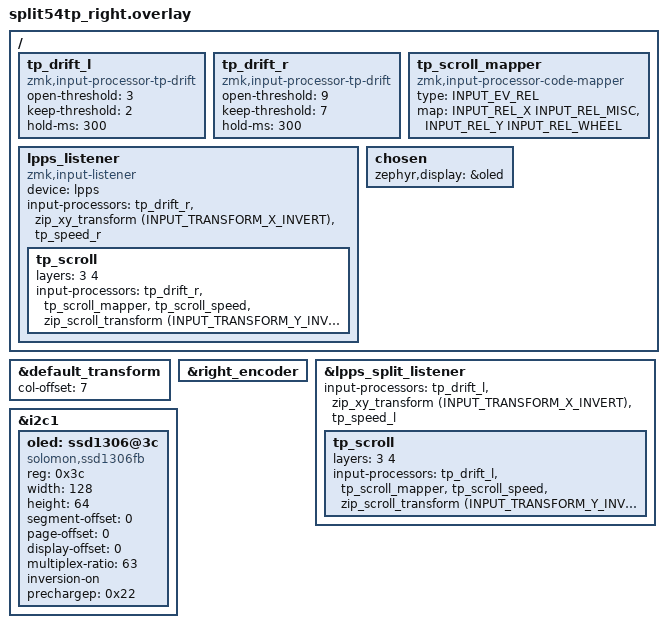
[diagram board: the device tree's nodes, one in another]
/*
 * split54tp 右半身 (セントラル)
 * USB/BLEでホストに接続する側。
 */

#include "split54tp.dtsi"
#include <input/processors.dtsi>
#include <dt-bindings/zmk/input_transform.h>

/* 右半身は transform の列 7-13 を使用 */
&default_transform {
    col-offset = <7>;
};

&right_encoder {
    status = "okay";

    /*
     * ⚠ 右基板は ENC1 を物理的に180度回転して実装している。
     *   実機で回転方向が左と逆だった場合は、下の2行のコメントを外して
     *   a/b を入れ替える (ファームウェアだけで直せる)。
     *
     * ★ 2026-09-05 実機で確認: 一般的なマウスホイールと回転方向が逆だった。
     *   予見どおりだったので、下の2行を有効化して a/b を入れ替える。
     *   左基板は回転させていないので入れ替えない。これで左右が揃う。
     *   元に戻すには下の2行を削除する (dtsi の a=D7 / b=D8 に戻る)。
     *
     * ★ 2026-09-26 rev.6 実機: この入れ替えがあると左右で回転方向が逆になった
     *   (左 = 一般的なマウスと同じ / 右 = 逆)。rev.6 の右基板は ENC1 を回転実装して
     *   いないため、入れ替えを外す (dtsi の a=D7 / b=D8 のまま)。
     *   rev.5 用の入れ替えは split54tp_right.overlay.bak-enc-20260926 に残してある。
     */
    // a-gpios = <&xiao_d 8 (GPIO_ACTIVE_HIGH | GPIO_PULL_UP)>;
    // b-gpios = <&xiao_d 7 (GPIO_ACTIVE_HIGH | GPIO_PULL_UP)>;
};

/*
 * ---- ポインティングスティック ---- 2026-09-26 有効化
 * 右はセントラル。
 *   ・自分の LPPS (dtsi の &lpps) → lpps_listener
 *   ・左の LPPS (input-split 経由) → lpps_split_listener
 *
 * ★ 軸の向き: 実機で「上に倒したのに下へ動く」等があれば、
 *   該当する listener に input-processors を足す (左は &lpps_split_listener に足す)。
 *     #include <dt-bindings/zmk/input_transform.h>
 *     input-processors = <&zip_xy_transform (INPUT_TRANSFORM_X_INVERT)>;
 *   使える値: INPUT_TRANSFORM_XY_SWAP / _X_INVERT / _Y_INVERT
 *   https://zmk.dev/docs/keymaps/input-processors/transformer
 */
/*
 * ★ 2026-11-11 (ユーザー指定) L1 / L2 を押している間、スティック (左右とも) を上下スクロールにする。
 *   ZMK の input listener の「レイヤーごとの差し替え」(子ノードの layers / input-processors) を使う。
 *   https://zmk.dev/docs/keymaps/input-processors/usage
 *   layers の 3 / 4 はキーマップの LOWER (L1) / RAISE (L2)。キーマップの #define と合わせること。
 *   中身: 上下 (Y) をホイールへ、左右 (X) は捨てる (tp_scroll_mapper) → 速さ (&tp_scroll_speed、split54tp.dtsi。設定レイヤーで上げ下げ)
 *         → ホイールの向きを逆にする (&zip_scroll_transform Y_INVERT。上に倒すと上へスクロール = Windows のふつうの向き。ユーザー: 向きは良い)。
 *   ★ 2026-11-11 最初は 1/8 固定 (&zip_y_scaler 1 8) で「爆速すぎ」(ユーザー) → 段で変えられる &tp_scroll_speed (既定 1/50) にした。
 *   L1 / L2 の間はカーソルが動かない (左右も捨てるので斜めに倒しても横スクロールしない)。感度 (tp_speed) は効かない。
 *   逆向きにしたいときは zip_scroll_transform を消す。
 */
/*
 * ★ 2026-11-11 (3 回目) ドリフト止め (ユーザー: 「左右どちらかは不明だがドリフトがひどい。何度 TP 校正をしてもすぐ動き始める」)。
 *   自作の input processor (src/pointing/input_processor_tp_drift.c) の「門」を、左右それぞれのいちばん前に置く
 *   (L1 / L2 のスクロールの差し替え tp_scroll にも。差し替えると元の並びは使われないため)。
 *   門が閉じている間は小さな動き (ドリフト) を捨てる。生の値 (絶対値) が open-threshold 以上で開き、
 *   hold-ms の間は通す。開いている間は keep-threshold 以上の値で延びる。
 *   値は推測で決めた (ドリフトの大きさはまだ測っていない)。F / J (TP 復旧) の 2 行目の V に、自分の側のドリフトの最大の値が出るので、
 *   それより 1 大きい open-threshold にする。止めたいときは open-threshold = <0>。
 *   (TP 復旧は 2026-11-11 に G / H へ移動)
 * ★ 2026-11-11 (4 回目) 右を open 9 / keep 7 に (左は 3 / 2 のまま)。実測 (ユーザー、H で 30 秒触らずに): 右は
 *   シュラウドとキャップを付けたまま V54、外して V5、もう一度 V6 (V34 は、前に押してからの部品を外した間を含むとみる。未確認)。
 *   最大 6 に余裕を見て、開くのは 9 以上、開いている間は 7 以上で延びる (ドリフトの 6 以下では開いたままにならない)。
 *   代わりに右は、ゆっくり倒し始めたときに 9 の力まで動かない。左のドリフトは未測定。
 */
/ {
    tp_drift_l: tp_drift_l {
        compatible = "zmk,input-processor-tp-drift";
        #input-processor-cells = <0>;
        open-threshold = <3>;
        keep-threshold = <2>;
        hold-ms = <300>;
    };

    tp_drift_r: tp_drift_r {
        compatible = "zmk,input-processor-tp-drift";
        #input-processor-cells = <0>;
        open-threshold = <9>;   /* ★ 2026-11-11 (4 回目) 3 → 9 */
        keep-threshold = <7>;   /* ★ 2026-11-11 (4 回目) 2 → 7 */
        hold-ms = <300>;
    };
};

/ {
    /* 上下 (Y) だけをホイールへ。左右 (X) は INPUT_REL_MISC にして捨てる (ZMK の input_listener.c は REL の X / Y / WHEEL / HWHEEL 以外を無視する) */
    tp_scroll_mapper: tp_scroll_mapper {
        compatible = "zmk,input-processor-code-mapper";
        #input-processor-cells = <0>;
        type = <INPUT_EV_REL>;
        map = <INPUT_REL_X INPUT_REL_MISC>, <INPUT_REL_Y INPUT_REL_WHEEL>;
    };

    lpps_listener: lpps_listener {
        compatible = "zmk,input-listener";
        device = <&lpps>;
        /* ★ 2026-11-04 &tp_speed_r = 右の感度 (split54tp.dtsi / 設定レイヤーで上げ下げ) */
        /* ★ 2026-11-11 (3 回目) いちばん前に &tp_drift_r (ドリフト止め) */
        input-processors = <&tp_drift_r &zip_xy_transform (INPUT_TRANSFORM_X_INVERT) &tp_speed_r>;

        /* ★ 2026-11-11 L1 (3) / L2 (4) の間は上下スクロール */
        tp_scroll {
            layers = <3 4>;
            input-processors = <&tp_drift_r &tp_scroll_mapper &tp_scroll_speed &zip_scroll_transform (INPUT_TRANSFORM_Y_INVERT)>;
        };
    };
};

/*
 * ⚠ 2026-09-26 一時停止: 左スティックがドリフトし続ける (倒しても反応しない)。
 *   ログで右は x=0 y=0 (z のみ) と確認、ドリフト源は左 (input-split 経由) と特定。
 *   左センサの半田を直したら status を "okay" に戻す。
 * ★ 2026-10-25 rev.7: センサを新品 (SK8707-01-004) に替えるので、左の受信を戻す。
 *   また左がドリフトするなら、下を "disabled" に戻して切り分ける。
 */
&lpps_split_listener {
    status = "okay";
    /* ★ 2026-11-04 &tp_speed_l = 左の感度。左のスティックの分もここ (右) で計算するので、感度だけなら左の書き直しは要らない */
    /* ★ 2026-11-11 (3 回目) いちばん前に &tp_drift_l (ドリフト止め) */
    input-processors = <&tp_drift_l &zip_xy_transform (INPUT_TRANSFORM_X_INVERT) &tp_speed_l>;

    /* ★ 2026-11-11 L1 (3) / L2 (4) の間は上下スクロール (右の lpps_listener と同じ) */
    tp_scroll {
        layers = <3 4>;
        input-processors = <&tp_drift_l &tp_scroll_mapper &tp_scroll_speed &zip_scroll_transform (INPUT_TRANSFORM_Y_INVERT)>;
    };
};

/*
 * ★ 2026-10-25 rev.7: スティックの X / Y の向きは未確認。
 *   rev.7 は LPPS のコネクタを −Y 向きにした (rev.6 から 180° 回した、keyboard-project/docs/rev7-修正計画.md §3-1)。
 *   ただし rev.6 でも正しい向きは確かめられていない (センサの故障のため) ので、補正の値は実機で決める。
 *   センサが届いたら、倒した向きとカーソルの動きを見て、上の説明の input-processors を足す。
 *
 * ★ 2026-10-31 実機 (基板に付ける前。軸を自分に向け、コネクタを手前にして確認): 上下はそのまま、左右が逆 → X だけ反転。
 *   左も LPPS を同じ向きに付ける (裏のシルクの「FPC」は左右とも手前) ので、左の受信 (&lpps_split_listener) にも同じ補正を入れた。
 *   左は実機で未確認。ここはセントラルで効くので、左のファームを書き直さなくてよい。
 */

/*
 * ---- 状態モニタ用 OLED (右 = セントラル) ---- 2026-09-26 追加 (試験)
 *   秋月 112031 / 0.96インチ 128x64 / SSD1315 / I2C 0x3C / D9=SDA D10=SCL
 *   I2C バス本体は split54tp.dtsi。ここには OLED ノードだけを置く。
 *   セントラルは出力先 (USB/BLE と接続先番号)・レイヤー・電池を表示できる。
 *   左 (ペリフェラル) で表示ありにすると左が機能しなくなる件の切り分けも兼ねる。
 */
/ {
    chosen {
        zephyr,display = &oled;
    };
};

&i2c1 {
    oled: ssd1306@3c {
        compatible = "solomon,ssd1306fb";
        reg = <0x3c>;
        width = <128>;
        height = <64>;
        segment-offset = <0>;
        page-offset = <0>;
        display-offset = <0>;
        multiplex-ratio = <63>;
        /* ★ 2026-09-27 実装向き (端子が手前) に合わせて 180° 回転。
         *   segment-remap と com-invdir を外すと左右・上下が同時に反転する。 */
        inversion-on;
        prechargep = <0x22>;
    };
};
